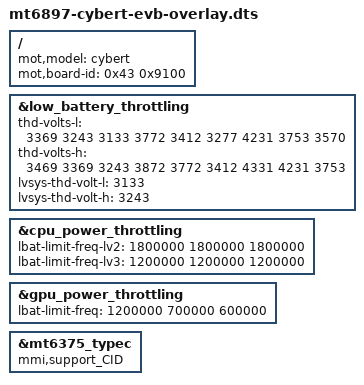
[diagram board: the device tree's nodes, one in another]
/* Copyright (c) 2023, Motorola Mobility Inc. All rights reserved.
 *
 * This program is free software; you can redistribute it and/or modify
 * it under the terms of the GNU General Public License version 2 and
 * only version 2 as published by the Free Software Foundation.
 *
 * This program is distributed in the hope that it will be useful,
 * but WITHOUT ANY WARRANTY; without even the implied warranty of
 * MERCHANTABILITY or FITNESS FOR A PARTICULAR PURPOSE.  See the
 * GNU General Public License for more details.
 */

/dts-v1/;
/plugin/;

#include "mediatek/mt6897-cybert-common-overlay.dtsi"

/* Board match root node */
/ {
	fragment@model {
		target-path = "/";
		__overlay__ {
			mot,model = "cybert";
			mot,board-id = <0x43 0x9100>;
		};
	};
};

&low_battery_throttling {
        thd-volts-l = <
                3369 3243 3133
                3772 3412 3277
                4231 3753 3570>;
        thd-volts-h = <
                3469 3369 3243
                3872 3772 3412
                4331 4231 3753>;
        lvsys-thd-volt-l = <3133>;
        lvsys-thd-volt-h = <3243>;
};

&cpu_power_throttling {
        lbat-limit-freq-lv2 = < 1800000  1800000 1800000>;
        lbat-limit-freq-lv3 = < 1200000  1200000 1200000>;
};

&gpu_power_throttling {
        lbat-limit-freq = <1200000 700000 600000>;
};

&mt6375_typec {
       mmi,support_CID;
};

#include <cybert_evb/cust.dtsi>
#include "mediatek/cust_cybert_camera_v4l2.dtsi"
/*End of this file, DO NOT ADD ANYTHING HERE*/
